VERSION ""

NS_ :

BS_:

BU_: PCU WaterPumpBatteryPack

BO_ 515 PCU_P01_Command: 8 PCU
 SG_ P01_PCU_D_DutyCycleSetpoint : 15|8@0+ (0.4,0) [0|100] "%"  WaterPumpBatteryPack
 SG_ P01_PCU_S_EnableCommand : 1|2@0+ (1,0) [0|3] ""  WaterPumpBatteryPack

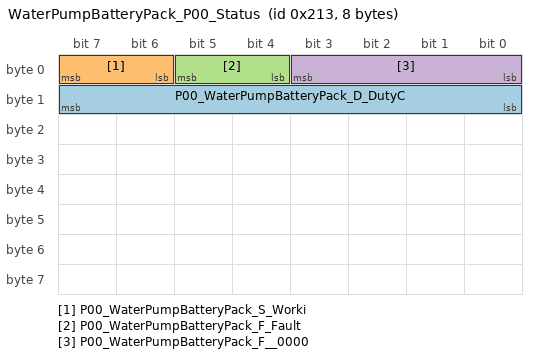
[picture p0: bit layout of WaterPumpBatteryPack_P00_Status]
BO_ 531 WaterPumpBatteryPack_P00_Status: 8 WaterPumpBatteryPack
 SG_ P00_WaterPumpBatteryPack_D_DutyC : 15|8@0+ (0.4,0) [0|100] "%"  PCU
 SG_ P00_WaterPumpBatteryPack_S_Worki : 7|2@0+ (1,0) [0|3] ""  PCU
 SG_ P00_WaterPumpBatteryPack_F_Fault : 5|2@0+ (1,0) [0|3] ""  PCU
 SG_ P00_WaterPumpBatteryPack_F__0000 : 3|4@0+ (1,0) [0|15] ""  PCU

CM_ SG_ 515 P01_PCU_D_DutyCycleSetpoint "Duty cycle set point";
CM_ SG_ 515 P01_PCU_S_EnableCommand "Enable command";
CM_ SG_ 531 P00_WaterPumpBatteryPack_D_DutyC "Duty cycle feedback";
CM_ SG_ 531 P00_WaterPumpBatteryPack_S_Worki "Working mode state";
CM_ SG_ 531 P00_WaterPumpBatteryPack_F_Fault "Fault level";
CM_ SG_ 531 P00_WaterPumpBatteryPack_F__0000 "Fault code (fault group)";
BA_DEF_ BO_  "TXRX" ENUM  "TX","RX";
BA_DEF_ SG_  "SigType" ENUM  "Default","Range","RangeSigned","ASCII","Discrete","Control","ReferencePGN","DTC","StringDelimiter","StringLength","StringLengthControl","MessageCounter","MessageChecksum";
BA_DEF_ SG_  "GenSigILSupport" ENUM  "No","Yes";
BA_DEF_ SG_  "GenSigSendType" ENUM  "Cyclic","OnWrite","OnWriteWithRepetition","OnChange","OnChangeWithRepetition","IfActive","IfActiveWithRepetition","NoSigSendType";
BA_DEF_ SG_  "SPN" INT 0 524287;
BA_DEF_ BO_  "GenMsgILSupport" ENUM  "No","Yes";
BA_DEF_ BO_  "GenMsgSendType" ENUM  "cyclic","NotUsed","NotUsed","NotUsed","NotUsed","NotUsed","NotUsed","IfActive","noMsgSendType";
BA_DEF_ BO_  "GenMsgRequestable" INT 0 1;
BA_DEF_ BO_  "GenMsgCycleTime" INT 0 3600000;
BA_DEF_  "DBName" STRING ;
BA_DEF_  "BusType" STRING ;
BA_DEF_ BO_  "VFrameFormat" ENUM  "StandardCAN","ExtendedCAN","reserved","J1939PG","reserved","reserved","reserved","reserved","reserved","reserved","reserved","reserved","reserved","reserved","StandardCAN_FD","ExtendedCAN_FD";
BA_DEF_ SG_  "SystemSignalLongSymbol" STRING ;
BA_DEF_DEF_  "TXRX" "TX";
BA_DEF_DEF_  "SigType" "Default";
BA_DEF_DEF_  "GenSigILSupport" "Yes";
BA_DEF_DEF_  "GenSigSendType" "NoSigSendType";
BA_DEF_DEF_  "SPN" 0;
BA_DEF_DEF_  "GenMsgILSupport" "Yes";
BA_DEF_DEF_  "GenMsgSendType" "noMsgSendType";
BA_DEF_DEF_  "GenMsgRequestable" 1;
BA_DEF_DEF_  "GenMsgCycleTime" 0;
BA_DEF_DEF_  "DBName" "";
BA_DEF_DEF_  "BusType" "CAN";
BA_DEF_DEF_  "VFrameFormat" "StandardCAN";
BA_DEF_DEF_  "SystemSignalLongSymbol" "";
BA_ "DBName" "WaterPumpBatteryPack";
BA_ "GenMsgSendType" BO_ 515 0;
BA_ "GenMsgCycleTime" BO_ 515 200;
BA_ "TXRX" BO_ 515 1;
BA_ "GenMsgSendType" BO_ 531 0;
BA_ "GenMsgCycleTime" BO_ 531 200;
BA_ "SPN" SG_ 515 P01_PCU_D_DutyCycleSetpoint 2010;
BA_ "GenSigSendType" SG_ 515 P01_PCU_D_DutyCycleSetpoint 0;
BA_ "SPN" SG_ 515 P01_PCU_S_EnableCommand 2009;
BA_ "GenSigSendType" SG_ 515 P01_PCU_S_EnableCommand 0;
BA_ "GenSigSendType" SG_ 531 P00_WaterPumpBatteryPack_D_DutyC 0;
BA_ "SPN" SG_ 531 P00_WaterPumpBatteryPack_D_DutyC 333;
BA_ "SystemSignalLongSymbol" SG_ 531 P00_WaterPumpBatteryPack_D_DutyC "P00_WaterPumpBatteryPack_D_DutyCycleFeedback";
BA_ "GenSigSendType" SG_ 531 P00_WaterPumpBatteryPack_S_Worki 0;
BA_ "SPN" SG_ 531 P00_WaterPumpBatteryPack_S_Worki 332;
BA_ "SystemSignalLongSymbol" SG_ 531 P00_WaterPumpBatteryPack_S_Worki "P00_WaterPumpBatteryPack_S_WorkingModeState";
BA_ "GenSigSendType" SG_ 531 P00_WaterPumpBatteryPack_F_Fault 0;
BA_ "SPN" SG_ 531 P00_WaterPumpBatteryPack_F_Fault 331;
BA_ "SystemSignalLongSymbol" SG_ 531 P00_WaterPumpBatteryPack_F_Fault "P00_WaterPumpBatteryPack_F_FaultLevel";
BA_ "GenSigSendType" SG_ 531 P00_WaterPumpBatteryPack_F__0000 0;
BA_ "SPN" SG_ 531 P00_WaterPumpBatteryPack_F__0000 330;
BA_ "SystemSignalLongSymbol" SG_ 531 P00_WaterPumpBatteryPack_F__0000 "P00_WaterPumpBatteryPack_F_FaultCode";
VAL_ 515 P01_PCU_S_EnableCommand 2 "Reserved" 3 "Reserved" 1 "On" 0 "Off" ;
VAL_ 531 P00_WaterPumpBatteryPack_S_Worki 2 "Reserved" 3 "Reserved" 1 "On" 0 "Off" ;
VAL_ 531 P00_WaterPumpBatteryPack_F_Fault 3 "Fault level 3" 2 "Fault level 2" 1 "Fault level 1" 0 "No fault" ;
VAL_ 531 P00_WaterPumpBatteryPack_F__0000 15 "Null" 8 "CAN signal lost fault" 7 "Low voltage fault" 6 "Locked rotor fault" 5 "Over temperature fault" 4 "Over voltage fault" 3 "No loading fault" 2 "Over current fault" 1 "Short circuit fault" 0 "No fault" ;
